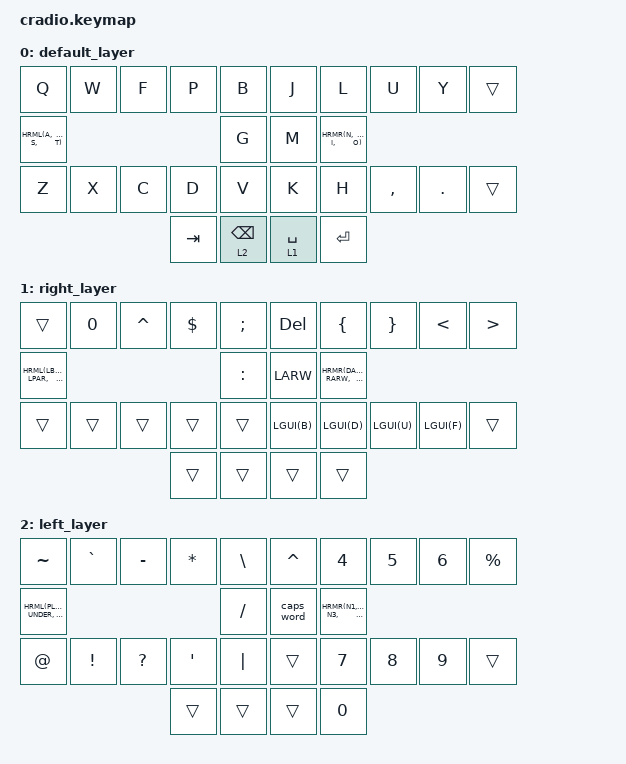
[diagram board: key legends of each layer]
// Copyright (c) 2022 The ZMK Contributors
// SPDX-License-Identifier: MIT

#include <behaviors.dtsi>
#include <dt-bindings/zmk/keys.h>
#include <dt-bindings/zmk/bt.h>

// Home row mods macro
#define HRML(k1,k2,k3,k4) &ht LSHFT k1  &ht LALT k2  &ht LCTRL k3  &ht LGUI k4
#define HRMR(k1,k2,k3,k4) &ht RGUI k1  &ht RCTRL k2  &ht RALT k3  &ht RSHFT k4

&caps_word {
   continue-list = <UNDERSCORE MINUS BACKSPACE>;
};

/ {
    combos {
        #include "combos.dtsi"    
    };
    
    behaviors {
        ht: hold_tap {
            label = "hold_tap";
            compatible = "zmk,behavior-hold-tap";
            #binding-cells = <2>;
            flavor = "tap-preferred";
            tapping-term-ms = <220>;
            quick-tap-ms = <150>;
            global-quick-tap;
            bindings = <&kp>, <&kp>;
        };
    };

    keymap {
        compatible = "zmk,keymap";
        default_layer {
            bindings = <
        //╭──────────┬──────────┬──────────┬──────────┬──────────╮   ╭──────────┬──────────┬──────────┬──────────┬──────────╮
        //│  Q       │  W       │  F       │  P       │  B       │   │  J       │  L       │  U       │  Y       │          │
            &kp Q      &kp W      &kp F      &kp P      &kp B          &kp J      &kp L      &kp U      &kp Y      &trans
        //├──────────┼──────────┼──────────┼──────────┼──────────┤   ├──────────┼──────────┼──────────┼──────────┼──────────┤
        //│  A       │  R       │  S       │  T       │  G       │   │  M       │  N       │  E       │  I       │  O       │
            HRML(A,     R,         S,         T)        &kp G          &kp M      HRMR(N,     E,         I,         O)
        //├──────────┼──────────┼──────────┼──────────┼──────────┤   ├──────────┼──────────┼──────────┼──────────┼──────────┤
        //│  Z       │  X       │  C       │  D       │  V       │   │  K       │  H       │  ,       │  .       │          │
            &kp Z      &kp X      &kp C      &kp D      &kp V          &kp K      &kp H      &kp COMMA  &kp DOT    &trans
        //╰──────────┴──────────┴──────────┼──────────┼──────────┤   ├──────────┼──────────┼──────────┴──────────┴──────────╯
                                            &kp TAB    &lt 2 BSPC     &lt 1 SPACE  &kp ENTER
        //                                 ╰──────────┴──────────╯   ╰──────────┴──────────╯
            >;
        };

        right_layer {
            bindings = <
        //╭──────────┬──────────┬──────────┬──────────┬──────────╮   ╭──────────┬──────────┬──────────┬──────────┬──────────╮
        //│          │  0       │  ^       │  $       │  ;       │   │  Delete  │ {        │ }        │ <        │  >       │
            &trans      &kp N0     &kp CARET  &kp DLLR  &kp SEMI       &kp DEL    &kp LBRC   &kp RBRC   &kp LT     &kp GT
        //├──────────┼──────────┼──────────┼──────────┼──────────┤   ├──────────┼──────────┼──────────┼──────────┼──────────┤
        //│ [        │  ]       │  (       │  )       │  :       │   │ LEFT     │ DOWN     │ UP       │ RIGHT    │  ;       │
            HRML(LBKT,  RBKT,      LPAR,      RPAR)     &kp COLON      &kp LARW   HRMR(DARW,  UARW,     RARW,      SEMI)
        //├──────────┼──────────┼──────────┼──────────┼──────────┤   ├──────────┼──────────┼──────────┼──────────┼──────────┤
        //│          │          │          │          │          │   │          │          │          │          │          │
            &trans     &trans     &trans     &trans     &trans      &kp LGUI(B) &kp LGUI(D) &kp LGUI(U) &kp LGUI(F)  &trans
        //╰──────────┴──────────┴──────────┼──────────┼──────────┤   ├──────────┼──────────┼──────────┴──────────┴──────────╯
                                             &trans     &trans         &trans     &trans
        //                                 ╰──────────┴──────────╯   ╰──────────┴──────────╯
            >;
        };

        left_layer {
            bindings = <
        //╭──────────┬──────────┬──────────┬──────────┬──────────╮   ╭──────────┬──────────┬──────────┬──────────┬──────────╮
        //│ ~        │  `       │  -       │  *       │  \       │   │  ^       │  4       │  5       │  6       │  %       │
            &kp TILDE  &kp GRAVE  &kp MINUS  &kp ASTRK  &kp BSLH       &kp CARET  &kp N4     &kp N5     &kp N6     &kp PRCNT
        //├──────────┼──────────┼──────────┼──────────┼──────────┤   ├──────────┼──────────┼──────────┼──────────┼──────────┤
        //│  +       │  =       │  _       │  "       │  /       │   │  CAPS_W  │  1       │  2       │  3       │  .       │
            HRML(PLUS, EQUAL,      UNDER,     DQT)      &kp FSLH      &caps_word   HRMR(N1,   N2,       N3,         DOT)
        //├──────────┼──────────┼──────────┼──────────┼──────────┤   ├──────────┼──────────┼──────────┼──────────┼──────────┤
        //│  @       │  !       │  ?       │  '       │  |       │   │          │  7       │  8       │  9       │          │
            &kp AT    &kp EXCL  &kp QMARK    &kp APOS   &kp PIPE        &trans     &kp N7     &kp N8     &kp N9     &trans
        //╰──────────┴──────────┴──────────┼──────────┼──────────┤   ├──────────┼──────────┼──────────┴──────────┴──────────╯
                                             &trans     &trans         &trans     &kp N0
        //                                 ╰──────────┴──────────╯   ╰──────────┴──────────╯
            >;
        };
    };
};
